# ESP32S31_RADIO register map
Vendor: Espressif; Series: ESP32-S31; File version: 3.52
Registers are 32-bit, read-write, no defined reset value unless marked. A register's access mark holds for its fields unless they carry their own. Offsets are from the block's base; [hi:lo] are bit positions; lines under a group give offsets from that group.

## HP_SYS_CLKRST_TIMG1 — HP system clock/reset registers: timer group 1's bus clock, reset and watchdog clock word.
Base 0x20587000
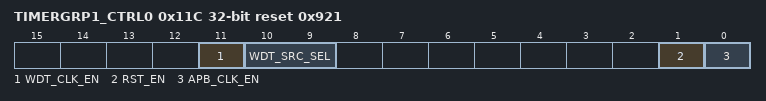
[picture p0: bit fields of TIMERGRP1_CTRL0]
0x11C TIMERGRP1_CTRL0 reset 0x921 — Timer group 1 bus clock, reset and timer and watchdog clock sources and enables.
  [11] WDT_CLK_EN — Watchdog clock enable.
  [10:9] WDT_SRC_SEL — Watchdog clock source: 0 XTAL, 1 RC_FAST, 2 PLL_F80M.
  [1] RST_EN — Holds timer group 1 in reset while set.
  [0] APB_CLK_EN — Timer group 1 bus clock enable.

## USB_SERIAL_JTAG — USB Serial/JTAG controller: the CDC-ACM data FIFO, its configuration and the two interrupts of the serial endpoints. The JTAG side and the other interrupt sources are not described.
Base 0x20391000
0x00 EP1 reset 0x0 — FIFO access for the CDC-ACM data IN and OUT endpoints: a write appends a byte to the IN FIFO, a read takes one from the OUT FIFO.
  [7:0] RDWR_BYTE — One byte of the IN or OUT FIFO.
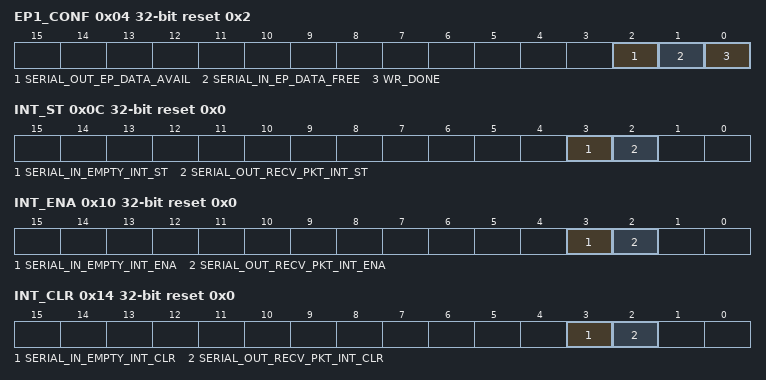
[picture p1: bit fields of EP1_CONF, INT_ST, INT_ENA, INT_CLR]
0x04 EP1_CONF reset 0x2 — Configuration and status of the CDC-ACM FIFOs.
  [2] SERIAL_OUT_EP_DATA_AVAIL ro — The OUT FIFO holds a byte to read.
  [1] SERIAL_IN_EP_DATA_FREE ro — The IN FIFO has room for a byte. After WR_DONE it stays clear until the host has read the packet.
  [0] WR_DONE wo — Writing one hands the bytes in the IN FIFO to the host as one packet; an empty FIFO sends a zero-length packet.
0x0C INT_ST ro reset 0x0 — Masked interrupt status of the serial endpoints.
  [3] SERIAL_IN_EMPTY_INT_ST — The IN endpoint became empty, and its interrupt is enabled.
  [2] SERIAL_OUT_RECV_PKT_INT_ST — The OUT endpoint received a packet, and its interrupt is enabled.
0x10 INT_ENA reset 0x0 — Interrupt enables of the serial endpoints.
  [3] SERIAL_IN_EMPTY_INT_ENA — Enables the IN endpoint's empty interrupt.
  [2] SERIAL_OUT_RECV_PKT_INT_ENA — Enables the OUT endpoint's packet-received interrupt.
0x14 INT_CLR wo reset 0x0 — Interrupt acknowledgement of the serial endpoints: writing one clears the event.
  [3] SERIAL_IN_EMPTY_INT_CLR — Writing one clears the IN endpoint's empty event.
  [2] SERIAL_OUT_RECV_PKT_INT_CLR — Writing one clears the OUT endpoint's packet-received event.

## USB_SERIAL_JTAG_PADS — USB Serial/JTAG pad configuration: the software override of the D+ and D- pull-ups and the pad enable.
Base 0x20391000
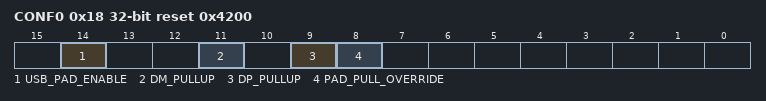
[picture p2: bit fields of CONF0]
0x18 CONF0 reset 0x4200 — PHY and pad configuration. Only the pull-up override and the pad enable are described.
  [14] USB_PAD_ENABLE — Enables the USB pad function.
  [11] DM_PULLUP — D- pull-up, while PAD_PULL_OVERRIDE is set.
  [9] DP_PULLUP — D+ pull-up, while PAD_PULL_OVERRIDE is set.
  [8] PAD_PULL_OVERRIDE — Software controls the D+ and D- pull-ups and pull-downs.

## PMU_CPU_STALL — Power management unit: the software stall request of each HP core.
Base 0x20704000
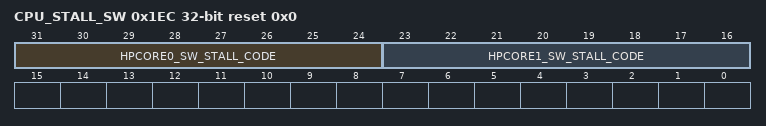
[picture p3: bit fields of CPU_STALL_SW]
0x1EC CPU_STALL_SW reset 0x0 — Software stall request codes of the two HP cores: 0x86 requests a stall, 0xFF lets the core run.
  [31:24] HPCORE0_SW_STALL_CODE — Stall request code of HP core 0.
  [23:16] HPCORE1_SW_STALL_CODE — Stall request code of HP core 1.

## HP_SYS_CORE_STALL_STATUS — HP system registers: whether each HP core is stalled.
Base 0x20586000
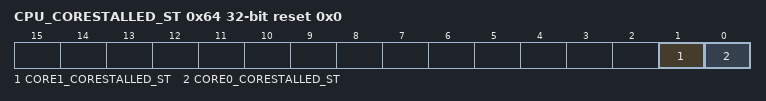
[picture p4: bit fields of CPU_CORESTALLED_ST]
0x64 CPU_CORESTALLED_ST ro reset 0x0 — The hardware's corestalled status of each HP core, separate from the stall request.
  [1] CORE1_CORESTALLED_ST — HP core 1 is stalled.
  [0] CORE0_CORESTALLED_ST — HP core 0 is stalled.

## HP_SYS_CLKRST_CORE — HP system clock/reset registers: HP core 1's clocks and global reset.
Base 0x20587000
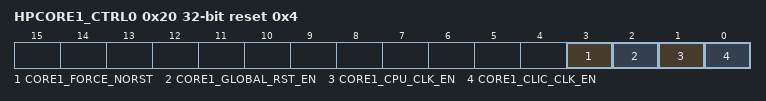
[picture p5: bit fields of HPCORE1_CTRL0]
0x20 HPCORE1_CTRL0 reset 0x4 — HP core 1's CLIC and CPU clock enables and its global reset.
  [3] CORE1_FORCE_NORST — Keeps HP core 1 out of reset.
  [2] CORE1_GLOBAL_RST_EN — Holds HP core 1 in its global reset while set.
  [1] CORE1_CPU_CLK_EN — HP core 1's CPU clock enable.
  [0] CORE1_CLIC_CLK_EN — HP core 1's CLIC clock enable.
